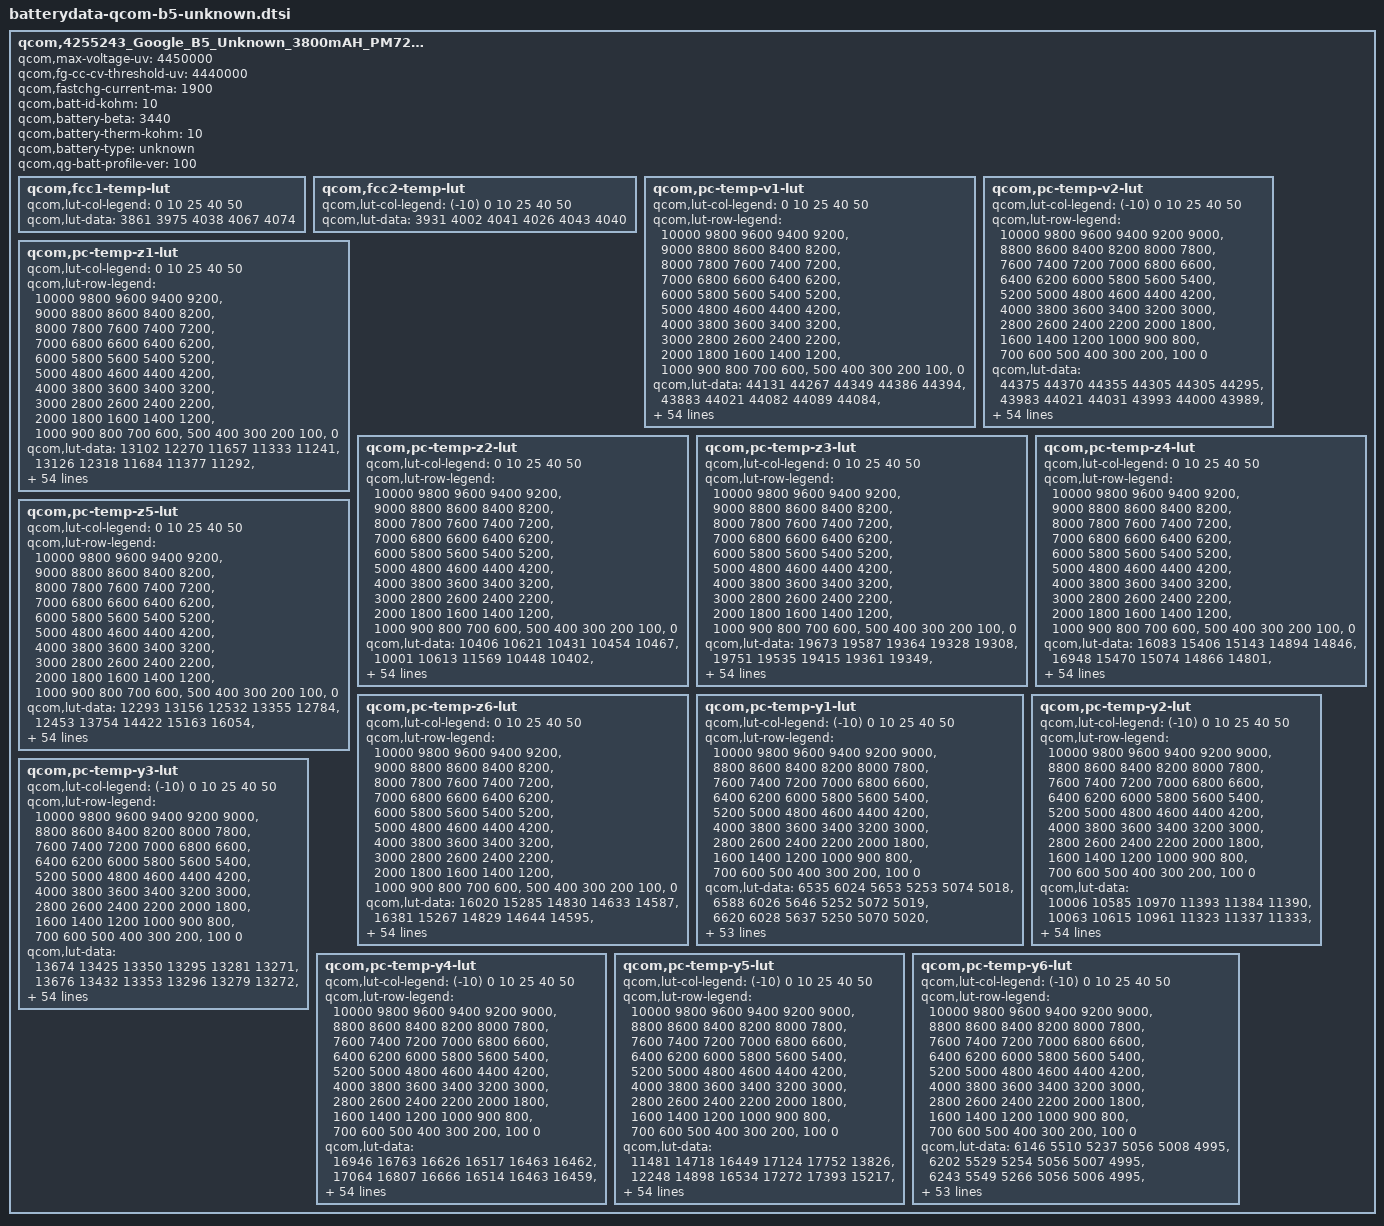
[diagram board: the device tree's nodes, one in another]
// SPDX-License-Identifier: GPL-2.0
qcom,4255243_Google_B5_Unknown_3800mAH_PM7250 {
	/* 4255243_Google_B5_ATL_3800mAH_PM7250_Nov13th2019 */
	qcom,max-voltage-uv = <4450000>;
	qcom,fg-cc-cv-threshold-uv = <4440000>;
	qcom,fastchg-current-ma = <1900>;
	qcom,batt-id-kohm = <10>;
	qcom,battery-beta = <3440>;
	qcom,battery-therm-kohm = <10>;
	qcom,battery-type = "unknown";
	qcom,qg-batt-profile-ver = <100>;

	qcom,fcc1-temp-lut {
		qcom,lut-col-legend = <0 10 25 40 50>;
		qcom,lut-data = <3861 3975 4038 4067 4074>;
	};

	qcom,fcc2-temp-lut {
		qcom,lut-col-legend = <(-10) 0 10 25 40 50>;
		qcom,lut-data = <3931 4002 4041 4026 4043 4040>;
	};

	qcom,pc-temp-v1-lut {
		qcom,lut-col-legend = <0 10 25 40 50>;
		qcom,lut-row-legend = <10000 9800 9600 9400 9200>,
			<9000 8800 8600 8400 8200>,
			<8000 7800 7600 7400 7200>,
			<7000 6800 6600 6400 6200>,
			<6000 5800 5600 5400 5200>,
			<5000 4800 4600 4400 4200>,
			<4000 3800 3600 3400 3200>,
			<3000 2800 2600 2400 2200>,
			<2000 1800 1600 1400 1200>,
			<1000 900 800 700 600>,
			<500 400 300 200 100>,
			<0>;
		qcom,lut-data = <44131 44267 44349 44386 44394>,
			<43883 44021 44082 44089 44084>,
			<43643 43780 43850 43846 43840>,
			<43408 43553 43614 43625 43620>,
			<43167 43319 43382 43402 43400>,
			<42924 43078 43150 43173 43172>,
			<42681 42829 42908 42936 42939>,
			<42437 42581 42660 42689 42699>,
			<42195 42334 42413 42441 42456>,
			<41958 42090 42167 42195 42212>,
			<41727 41850 41925 41952 41967>,
			<41500 41614 41684 41712 41728>,
			<41277 41385 41448 41476 41492>,
			<41062 41164 41220 41246 41261>,
			<40856 40949 41000 41022 41036>,
			<40658 40738 40788 40806 40818>,
			<40457 40533 40582 40597 40609>,
			<40251 40342 40384 40396 40408>,
			<40062 40163 40199 40207 40218>,
			<39903 39991 40021 40027 40036>,
			<39758 39831 39854 39853 39860>,
			<39609 39667 39698 39692 39695>,
			<39459 39469 39507 39513 39517>,
			<39308 39237 39206 39266 39281>,
			<39155 39024 38937 39013 39037>,
			<39000 38822 38814 38859 38874>,
			<38838 38664 38729 38749 38753>,
			<38664 38578 38641 38643 38642>,
			<38536 38516 38553 38540 38537>,
			<38453 38454 38469 38444 38440>,
			<38392 38395 38388 38357 38350>,
			<38344 38339 38314 38279 38268>,
			<38307 38286 38252 38211 38194>,
			<38274 38237 38198 38151 38128>,
			<38245 38197 38150 38095 38065>,
			<38216 38163 38108 38043 38008>,
			<38188 38126 38066 37991 37948>,
			<38161 38091 38026 37939 37879>,
			<38121 38045 37979 37880 37803>,
			<38051 37967 37902 37801 37717>,
			<37958 37856 37789 37696 37619>,
			<37843 37734 37667 37579 37507>,
			<37700 37592 37531 37445 37372>,
			<37537 37425 37372 37289 37217>,
			<37372 37262 37205 37126 37058>,
			<37234 37150 37096 37030 36966>,
			<37196 37119 37068 37006 36945>,
			<37164 37095 37047 36990 36929>,
			<37130 37072 37031 36975 36913>,
			<37099 37042 37000 36939 36871>,
			<37051 36886 36841 36743 36656>,
			<36824 36479 36437 36315 36216>,
			<36347 35891 35865 35738 35639>,
			<35676 35069 35086 34950 34853>,
			<34551 33643 33887 33727 33627>,
			<30000 30000 30000 30000 30000>;
	};

	qcom,pc-temp-v2-lut {
		qcom,lut-col-legend = <(-10) 0 10 25 40 50>;
		qcom,lut-row-legend = <10000 9800 9600 9400 9200 9000>,
			<8800 8600 8400 8200 8000 7800>,
			<7600 7400 7200 7000 6800 6600>,
			<6400 6200 6000 5800 5600 5400>,
			<5200 5000 4800 4600 4400 4200>,
			<4000 3800 3600 3400 3200 3000>,
			<2800 2600 2400 2200 2000 1800>,
			<1600 1400 1200 1000 900 800>,
			<700 600 500 400 300 200>,
			<100 0>;
		qcom,lut-data = <44375 44370 44355 44305 44305 44295>,
			<43983 44021 44031 43993 44000 43989>,
			<43642 43713 43739 43710 43722 43711>,
			<43362 43452 43486 43460 43474 43463>,
			<43130 43231 43265 43239 43252 43241>,
			<42895 43002 43035 43009 43023 43012>,
			<42640 42760 42790 42767 42782 42773>,
			<42388 42514 42543 42522 42538 42531>,
			<42164 42263 42295 42277 42294 42288>,
			<41955 42011 42047 42031 42048 42044>,
			<41706 41772 41803 41791 41809 41804>,
			<41375 41545 41563 41553 41572 41567>,
			<41100 41322 41328 41320 41340 41335>,
			<40972 41101 41097 41091 41112 41107>,
			<40873 40887 40875 40870 40890 40886>,
			<40647 40692 40668 40657 40675 40673>,
			<40166 40507 40469 40452 40467 40468>,
			<39772 40281 40274 40256 40269 40270>,
			<39574 39989 40083 40068 40080 40080>,
			<39410 39708 39872 39882 39897 39897>,
			<39217 39476 39614 39700 39729 39731>,
			<39009 39265 39357 39509 39549 39556>,
			<38812 39067 39142 39276 39311 39323>,
			<38614 38882 38949 39017 39048 39061>,
			<38448 38714 38780 38825 38859 38870>,
			<38340 38560 38632 38683 38717 38726>,
			<38257 38416 38498 38561 38594 38600>,
			<38187 38265 38378 38448 38482 38488>,
			<38127 38126 38268 38347 38382 38387>,
			<38071 38042 38165 38253 38289 38294>,
			<38018 37988 38070 38166 38203 38208>,
			<37966 37941 37985 38088 38126 38130>,
			<37910 37896 37906 38015 38056 38059>,
			<37851 37853 37845 37948 37989 37989>,
			<37791 37807 37806 37886 37925 37923>,
			<37731 37760 37772 37826 37858 37852>,
			<37667 37708 37733 37761 37771 37752>,
			<37597 37651 37692 37693 37668 37627>,
			<37521 37586 37640 37619 37569 37516>,
			<37439 37508 37571 37538 37474 37420>,
			<37351 37419 37483 37456 37391 37336>,
			<37261 37315 37366 37370 37306 37252>,
			<37171 37198 37215 37240 37176 37119>,
			<37089 37064 37051 37107 37046 36986>,
			<37004 36900 36869 36932 36888 36836>,
			<36918 36780 36778 36884 36854 36804>,
			<36871 36741 36746 36866 36846 36793>,
			<36830 36706 36714 36851 36831 36779>,
			<36785 36671 36674 36829 36806 36754>,
			<36743 36630 36608 36779 36745 36689>,
			<36690 36566 36422 36592 36486 36398>,
			<36600 36357 35971 36155 35987 35905>,
			<36417 35780 35321 35549 35334 35249>,
			<36071 34845 34346 34712 34414 34338>,
			<35286 33494 32805 33453 32968 32877>,
			<34418 31790 27248 29348 28016 28016>;
	};

	qcom,pc-temp-z1-lut {
		qcom,lut-col-legend = <0 10 25 40 50>;
		qcom,lut-row-legend = <10000 9800 9600 9400 9200>,
			<9000 8800 8600 8400 8200>,
			<8000 7800 7600 7400 7200>,
			<7000 6800 6600 6400 6200>,
			<6000 5800 5600 5400 5200>,
			<5000 4800 4600 4400 4200>,
			<4000 3800 3600 3400 3200>,
			<3000 2800 2600 2400 2200>,
			<2000 1800 1600 1400 1200>,
			<1000 900 800 700 600>,
			<500 400 300 200 100>,
			<0>;
		qcom,lut-data = <13102 12270 11657 11333 11241>,
			<13126 12318 11684 11377 11292>,
			<13129 12315 11683 11378 11297>,
			<13133 12278 11671 11371 11293>,
			<13133 12259 11659 11363 11291>,
			<13128 12248 11647 11360 11290>,
			<13119 12240 11637 11358 11288>,
			<13094 12232 11628 11356 11287>,
			<13064 12217 11621 11355 11287>,
			<13034 12198 11615 11353 11286>,
			<12999 12191 11612 11352 11286>,
			<12984 12187 11612 11351 11286>,
			<12979 12187 11612 11351 11286>,
			<12977 12192 11612 11351 11286>,
			<12972 12196 11611 11351 11287>,
			<12960 12191 11611 11351 11288>,
			<12957 12181 11612 11352 11289>,
			<12961 12178 11613 11354 11290>,
			<12963 12181 11615 11356 11292>,
			<12965 12184 11618 11358 11294>,
			<12967 12192 11621 11360 11296>,
			<12975 12203 11626 11361 11297>,
			<12998 12206 11630 11363 11298>,
			<13011 12207 11633 11365 11300>,
			<13007 12209 11637 11368 11302>,
			<13000 12212 11641 11371 11305>,
			<12999 12216 11646 11375 11309>,
			<13010 12219 11652 11379 11312>,
			<13016 12223 11658 11383 11315>,
			<13016 12230 11664 11388 11318>,
			<13017 12244 11669 11391 11321>,
			<13022 12255 11673 11395 11324>,
			<13030 12262 11678 11398 11326>,
			<13039 12267 11684 11402 11329>,
			<13054 12270 11688 11406 11332>,
			<13072 12271 11694 11409 11334>,
			<13085 12274 11700 11413 11337>,
			<13096 12282 11708 11416 11340>,
			<13103 12294 11717 11420 11344>,
			<13112 12314 11722 11423 11345>,
			<13122 12335 11727 11426 11347>,
			<13129 12336 11732 11430 11348>,
			<13140 12327 11741 11434 11350>,
			<13180 12340 11748 11436 11352>,
			<13201 12363 11753 11438 11353>,
			<13191 12359 11765 11444 11356>,
			<13196 12368 11760 11445 11356>,
			<13189 12358 11763 11445 11356>,
			<13199 12364 11766 11445 11358>,
			<13158 12360 11770 11448 11360>,
			<13195 12384 11780 11453 11363>,
			<13225 12388 11788 11461 11369>,
			<13209 12413 11806 11471 11376>,
			<13290 12448 11825 11484 11388>,
			<13290 12448 11825 11484 11388>,
			<13290 12448 11825 11484 11388>;
	};

	qcom,pc-temp-z2-lut {
		qcom,lut-col-legend = <0 10 25 40 50>;
		qcom,lut-row-legend = <10000 9800 9600 9400 9200>,
			<9000 8800 8600 8400 8200>,
			<8000 7800 7600 7400 7200>,
			<7000 6800 6600 6400 6200>,
			<6000 5800 5600 5400 5200>,
			<5000 4800 4600 4400 4200>,
			<4000 3800 3600 3400 3200>,
			<3000 2800 2600 2400 2200>,
			<2000 1800 1600 1400 1200>,
			<1000 900 800 700 600>,
			<500 400 300 200 100>,
			<0>;
		qcom,lut-data = <10406 10621 10431 10454 10467>,
			<10001 10613 11569 10448 10402>,
			<10032 10256 11084 10547 10437>,
			<10080 10223 10461 10531 10469>,
			<10120 10182 10382 10696 10584>,
			<10160 10148 10343 10889 10514>,
			<10173 10115 10308 10905 10464>,
			<10167 10097 10279 10629 10442>,
			<10159 10093 10284 10438 10418>,
			<10148 10091 10434 10434 10362>,
			<10132 10095 10570 10434 10302>,
			<10115 10113 10609 10512 10303>,
			<10096 10131 10633 10741 10335>,
			<10079 10144 10637 10838 10353>,
			<10063 10156 10629 10825 10360>,
			<10049 10168 10632 10820 10365>,
			<10044 10181 10669 10868 10382>,
			<10040 10212 10701 10918 10405>,
			<10038 10306 10620 10827 10421>,
			<10043 10366 10475 10531 10442>,
			<10052 10335 10454 10441 10465>,
			<10060 10290 10458 10454 10499>,
			<10069 10304 10462 10462 10527>,
			<10080 10342 10470 10446 10537>,
			<10100 10354 10477 10424 10541>,
			<10122 10339 10455 10449 10554>,
			<10136 10321 10411 10538 10598>,
			<10147 10309 10419 10591 10602>,
			<10154 10299 10509 10616 10496>,
			<10160 10299 10554 10627 10401>,
			<10164 10313 10536 10583 10376>,
			<10168 10325 10513 10518 10361>,
			<10171 10331 10500 10503 10364>,
			<10174 10336 10485 10503 10381>,
			<10177 10339 10485 10519 10410>,
			<10180 10342 10506 10604 10473>,
			<10184 10346 10530 10686 10549>,
			<10189 10353 10549 10723 10633>,
			<10196 10362 10571 10752 10710>,
			<10210 10376 10605 10787 10724>,
			<10227 10391 10645 10825 10701>,
			<10240 10392 10653 10832 10691>,
			<10255 10388 10644 10801 10686>,
			<10280 10394 10644 10790 10674>,
			<10438 10446 10659 10794 10653>,
			<10648 10609 10731 10733 10687>,
			<10575 10637 10717 10710 10689>,
			<10487 10682 10685 10701 10673>,
			<10382 10889 10678 10692 10685>,
			<10361 11053 10690 10760 10784>,
			<10269 10905 10869 10724 10618>,
			<10257 10876 10933 10608 10441>,
			<10148 10743 10925 10515 10370>,
			<9981 10452 10896 10435 10355>,
			<9981 10452 10896 10435 10355>,
			<9981 10452 10896 10435 10355>;
	};

	qcom,pc-temp-z3-lut {
		qcom,lut-col-legend = <0 10 25 40 50>;
		qcom,lut-row-legend = <10000 9800 9600 9400 9200>,
			<9000 8800 8600 8400 8200>,
			<8000 7800 7600 7400 7200>,
			<7000 6800 6600 6400 6200>,
			<6000 5800 5600 5400 5200>,
			<5000 4800 4600 4400 4200>,
			<4000 3800 3600 3400 3200>,
			<3000 2800 2600 2400 2200>,
			<2000 1800 1600 1400 1200>,
			<1000 900 800 700 600>,
			<500 400 300 200 100>,
			<0>;
		qcom,lut-data = <19673 19587 19364 19328 19308>,
			<19751 19535 19415 19361 19349>,
			<19846 19637 19437 19379 19355>,
			<19895 19678 19518 19389 19362>,
			<19885 19689 19522 19437 19396>,
			<19844 19691 19523 19447 19399>,
			<19809 19690 19521 19448 19399>,
			<19779 19689 19517 19435 19392>,
			<19761 19682 19513 19420 19382>,
			<19760 19667 19510 19409 19377>,
			<19760 19653 19506 19399 19372>,
			<19763 19637 19501 19399 19367>,
			<19776 19623 19495 19406 19362>,
			<19790 19608 19485 19405 19358>,
			<19800 19596 19471 19396 19355>,
			<19811 19592 19463 19389 19351>,
			<19812 19589 19459 19387 19346>,
			<19800 19588 19456 19384 19341>,
			<19788 19585 19445 19376 19338>,
			<19777 19581 19431 19361 19336>,
			<19769 19572 19425 19356 19335>,
			<19767 19561 19422 19355 19336>,
			<19770 19567 19421 19354 19337>,
			<19772 19591 19437 19353 19332>,
			<19775 19600 19451 19352 19324>,
			<19777 19598 19440 19349 19326>,
			<19782 19593 19417 19342 19337>,
			<19791 19585 19413 19342 19347>,
			<19796 19573 19419 19372 19359>,
			<19792 19570 19426 19394 19366>,
			<19785 19569 19446 19394 19365>,
			<19779 19569 19464 19392 19361>,
			<19770 19573 19462 19388 19357>,
			<19763 19577 19456 19379 19351>,
			<19758 19576 19450 19372 19346>,
			<19752 19572 19444 19369 19341>,
			<19746 19569 19438 19366 19339>,
			<19738 19566 19434 19364 19340>,
			<19730 19563 19431 19362 19342>,
			<19722 19557 19428 19361 19342>,
			<19713 19549 19426 19361 19342>,
			<19701 19544 19423 19360 19341>,
			<19687 19541 19419 19356 19336>,
			<19669 19534 19414 19356 19336>,
			<19606 19513 19406 19357 19339>,
			<19524 19466 19387 19341 19331>,
			<19425 19450 19385 19339 19323>,
			<19327 19430 19383 19337 19322>,
			<19316 19361 19375 19332 19320>,
			<19312 19329 19371 19327 19313>,
			<19307 19385 19349 19338 19331>,
			<19317 19344 19336 19346 19344>,
			<19325 19331 19331 19349 19346>,
			<19357 19344 19324 19351 19334>,
			<19357 19344 19324 19351 19334>,
			<19357 19344 19324 19351 19334>;
	};

	qcom,pc-temp-z4-lut {
		qcom,lut-col-legend = <0 10 25 40 50>;
		qcom,lut-row-legend = <10000 9800 9600 9400 9200>,
			<9000 8800 8600 8400 8200>,
			<8000 7800 7600 7400 7200>,
			<7000 6800 6600 6400 6200>,
			<6000 5800 5600 5400 5200>,
			<5000 4800 4600 4400 4200>,
			<4000 3800 3600 3400 3200>,
			<3000 2800 2600 2400 2200>,
			<2000 1800 1600 1400 1200>,
			<1000 900 800 700 600>,
			<500 400 300 200 100>,
			<0>;
		qcom,lut-data = <16083 15406 15143 14894 14846>,
			<16948 15470 15074 14866 14801>,
			<16671 15464 14929 14807 14759>,
			<16275 15551 15086 14801 14743>,
			<16037 15332 15035 14860 14813>,
			<15851 15179 14943 14797 14781>,
			<15701 15080 14888 14767 14758>,
			<15582 15006 14848 14755 14743>,
			<15478 14952 14812 14747 14733>,
			<15379 14909 14773 14743 14727>,
			<15286 14872 14744 14738 14722>,
			<15204 14838 14729 14725 14716>,
			<15130 14819 14718 14699 14709>,
			<15062 14811 14714 14685 14702>,
			<14992 14805 14712 14681 14694>,
			<14929 14796 14710 14677 14687>,
			<14908 14787 14701 14669 14681>,
			<14902 14776 14693 14660 14676>,
			<14896 14755 14697 14659 14669>,
			<14878 14742 14707 14669 14662>,
			<14851 14740 14710 14674 14659>,
			<14831 14742 14711 14676 14661>,
			<14813 14756 14717 14680 14663>,
			<14805 14788 14805 14745 14721>,
			<14809 14825 14887 14833 14808>,
			<14820 14877 14888 14841 14813>,
			<14842 14911 14883 14835 14791>,
			<14889 14904 14874 14823 14766>,
			<14911 14885 14849 14775 14736>,
			<14910 14867 14820 14731 14710>,
			<14908 14849 14784 14713 14696>,
			<14903 14832 14754 14701 14686>,
			<14889 14817 14746 14696 14679>,
			<14874 14803 14742 14692 14674>,
			<14861 14794 14741 14691 14672>,
			<14848 14786 14740 14693 14675>,
			<14834 14780 14740 14696 14679>,
			<14820 14773 14741 14702 14688>,
			<14806 14770 14742 14709 14698>,
			<14794 14769 14746 14716 14701>,
			<14782 14769 14753 14722 14702>,
			<14774 14764 14753 14722 14701>,
			<14766 14747 14739 14714 14698>,
			<14750 14734 14730 14710 14697>,
			<14738 14718 14721 14709 14697>,
			<14738 14688 14687 14685 14675>,
			<14848 14696 14676 14676 14672>,
			<14949 14705 14664 14659 14654>,
			<14956 14773 14655 14643 14636>,
			<14957 14803 14653 14643 14637>,
			<14953 14745 14692 14656 14641>,
			<14947 14803 14717 14657 14638>,
			<14964 14830 14723 14654 14637>,
			<14961 14834 14733 14653 14647>,
			<14961 14834 14733 14653 14647>,
			<14961 14834 14733 14653 14647>;
	};

	qcom,pc-temp-z5-lut {
		qcom,lut-col-legend = <0 10 25 40 50>;
		qcom,lut-row-legend = <10000 9800 9600 9400 9200>,
			<9000 8800 8600 8400 8200>,
			<8000 7800 7600 7400 7200>,
			<7000 6800 6600 6400 6200>,
			<6000 5800 5600 5400 5200>,
			<5000 4800 4600 4400 4200>,
			<4000 3800 3600 3400 3200>,
			<3000 2800 2600 2400 2200>,
			<2000 1800 1600 1400 1200>,
			<1000 900 800 700 600>,
			<500 400 300 200 100>,
			<0>;
		qcom,lut-data = <12293 13156 12532 13355 12784>,
			<12453 13754 14422 15163 16054>,
			<12957 15106 16018 17844 18301>,
			<13338 14528 16301 18627 19942>,
			<13419 15048 16520 18153 18775>,
			<13450 15583 16935 19704 19527>,
			<13489 16172 17347 20324 19800>,
			<13543 16711 17849 20235 19591>,
			<13623 17083 18472 19921 19374>,
			<13776 17433 20289 19310 19290>,
			<14050 18043 22195 18744 19223>,
			<14403 18972 23696 19476 19130>,
			<14947 19389 24901 22073 19020>,
			<15649 19407 24723 23917 19009>,
			<16772 19429 23593 24484 19328>,
			<18150 20112 23210 25234 19581>,
			<18754 21600 24318 27271 19534>,
			<18981 22288 25461 29264 19455>,
			<19203 22460 24598 27985 19688>,
			<19559 22841 22772 22979 20755>,
			<20120 23891 22728 21645 22004>,
			<21309 25775 23078 22313 23760>,
			<24451 31115 23929 22704 24817>,
			<28024 42137 29597 21995 22069>,
			<31436 45946 34682 20539 17581>,
			<34969 41961 30489 18616 16262>,
			<38584 36627 21789 15878 15607>,
			<42636 31886 19364 15234 15529>,
			<44278 27483 18860 17213 16829>,
			<42459 26419 18904 19659 18539>,
			<39543 26203 22395 21826 19960>,
			<37381 26160 27000 23918 21385>,
			<35429 28001 29443 25287 22758>,
			<34140 30691 31248 26290 24095>,
			<33403 32017 32297 27538 25237>,
			<32829 32926 33057 29459 26298>,
			<32177 33643 33338 30530 26983>,
			<31538 34328 32888 29718 27123>,
			<31436 34681 32003 28065 26935>,
			<32569 33964 30626 26338 26056>,
			<33604 32664 28655 24322 23847>,
			<32894 32222 27653 23135 22200>,
			<31493 32071 27269 22530 21029>,
			<31136 31706 26227 22021 20371>,
			<28593 30408 25013 21535 20103>,
			<22210 27405 26445 21039 20567>,
			<15973 23201 25897 21501 18989>,
			<12140 18853 26173 22734 20922>,
			<11837 14214 24737 25103 24909>,
			<11756 12676 23814 24037 23376>,
			<11724 15263 17524 20441 22764>,
			<11899 13138 14566 19640 24866>,
			<11819 12455 13907 19931 24559>,
			<12099 12583 13302 19594 18586>,
			<12099 12583 13302 19594 18586>,
			<12099 12583 13302 19594 18586>;
	};

	qcom,pc-temp-z6-lut {
		qcom,lut-col-legend = <0 10 25 40 50>;
		qcom,lut-row-legend = <10000 9800 9600 9400 9200>,
			<9000 8800 8600 8400 8200>,
			<8000 7800 7600 7400 7200>,
			<7000 6800 6600 6400 6200>,
			<6000 5800 5600 5400 5200>,
			<5000 4800 4600 4400 4200>,
			<4000 3800 3600 3400 3200>,
			<3000 2800 2600 2400 2200>,
			<2000 1800 1600 1400 1200>,
			<1000 900 800 700 600>,
			<500 400 300 200 100>,
			<0>;
		qcom,lut-data = <16020 15285 14830 14633 14587>,
			<16381 15267 14829 14644 14595>,
			<16273 15301 14774 14627 14580>,
			<16105 15342 14878 14629 14576>,
			<15974 15240 14856 14677 14625>,
			<15851 15165 14814 14660 14615>,
			<15749 15114 14787 14645 14604>,
			<15667 15071 14765 14632 14594>,
			<15597 15035 14746 14621 14585>,
			<15537 15004 14727 14613 14579>,
			<15485 14977 14712 14606 14574>,
			<15444 14951 14702 14599 14568>,
			<15411 14934 14694 14592 14563>,
			<15382 14923 14686 14585 14557>,
			<15353 14914 14678 14579 14552>,
			<15326 14907 14671 14573 14547>,
			<15311 14900 14666 14568 14541>,
			<15303 14893 14661 14563 14536>,
			<15295 14883 14657 14558 14532>,
			<15282 14875 14653 14554 14527>,
			<15269 14872 14653 14553 14526>,
			<15265 14870 14652 14554 14527>,
			<15264 14877 14655 14555 14528>,
			<15263 14906 14701 14583 14552>,
			<15268 14931 14745 14621 14586>,
			<15278 14953 14741 14623 14589>,
			<15293 14966 14730 14619 14586>,
			<15321 14961 14722 14614 14582>,
			<15334 14948 14716 14609 14576>,
			<15334 14940 14711 14604 14570>,
			<15333 14934 14707 14598 14564>,
			<15330 14929 14704 14592 14558>,
			<15321 14926 14700 14586 14552>,
			<15314 14923 14696 14580 14546>,
			<15309 14920 14693 14577 14543>,
			<15305 14917 14690 14576 14542>,
			<15301 14916 14688 14576 14542>,
			<15296 14916 14688 14577 14546>,
			<15295 14916 14688 14580 14552>,
			<15294 14916 14690 14582 14553>,
			<15294 14916 14693 14585 14553>,
			<15293 14915 14693 14586 14553>,
			<15292 14912 14687 14581 14549>,
			<15287 14907 14682 14580 14549>,
			<15264 14897 14677 14580 14551>,
			<15236 14868 14655 14562 14538>,
			<15232 14863 14651 14557 14532>,
			<15227 14858 14644 14549 14524>,
			<15225 14853 14637 14539 14514>,
			<15227 14853 14636 14538 14512>,
			<15232 14860 14644 14549 14524>,
			<15245 14872 14652 14556 14532>,
			<15269 14886 14657 14559 14535>,
			<15304 14911 14663 14562 14536>,
			<15304 14911 14663 14562 14536>,
			<15304 14911 14663 14562 14536>;
	};

	qcom,pc-temp-y1-lut {
		qcom,lut-col-legend = <(-10) 0 10 25 40 50>;
		qcom,lut-row-legend = <10000 9800 9600 9400 9200 9000>,
			<8800 8600 8400 8200 8000 7800>,
			<7600 7400 7200 7000 6800 6600>,
			<6400 6200 6000 5800 5600 5400>,
			<5200 5000 4800 4600 4400 4200>,
			<4000 3800 3600 3400 3200 3000>,
			<2800 2600 2400 2200 2000 1800>,
			<1600 1400 1200 1000 900 800>,
			<700 600 500 400 300 200>,
			<100 0>;
		qcom,lut-data = <6535 6024 5653 5253 5074 5018>,
			<6588 6026 5646 5252 5072 5019>,
			<6620 6028 5637 5250 5070 5020>,
			<6638 6030 5629 5247 5068 5020>,
			<6645 6032 5623 5245 5066 5019>,
			<6646 6034 5623 5241 5064 5019>,
			<6628 6036 5626 5237 5062 5018>,
			<6609 6037 5628 5234 5060 5017>,
			<6617 6034 5620 5230 5059 5016>,
			<6635 6026 5607 5228 5058 5015>,
			<6640 6025 5606 5225 5057 5015>,
			<6632 6026 5610 5223 5056 5015>,
			<6626 6027 5612 5221 5056 5016>,
			<6638 6035 5609 5220 5056 5016>,
			<6662 6043 5605 5220 5056 5016>,
			<6670 6046 5603 5220 5056 5016>,
			<6664 6047 5602 5219 5056 5015>,
			<6660 6045 5604 5220 5056 5015>,
			<6660 6036 5608 5223 5057 5017>,
			<6659 6030 5611 5225 5059 5018>,
			<6659 6036 5612 5227 5059 5019>,
			<6658 6046 5613 5230 5060 5019>,
			<6657 6045 5613 5233 5061 5019>,
			<6644 6038 5616 5236 5062 5020>,
			<6632 6038 5620 5238 5063 5021>,
			<6635 6050 5625 5241 5065 5023>,
			<6642 6061 5630 5243 5067 5025>,
			<6647 6066 5634 5246 5068 5026>,
			<6661 6070 5637 5250 5070 5027>,
			<6670 6070 5637 5255 5072 5028>,
			<6675 6068 5637 5260 5075 5030>,
			<6683 6066 5637 5266 5078 5031>,
			<6681 6061 5640 5271 5080 5033>,
			<6668 6057 5642 5277 5083 5035>,
			<6661 6063 5646 5281 5086 5037>,
			<6667 6076 5650 5285 5089 5039>,
			<6673 6081 5649 5286 5091 5040>,
			<6666 6079 5646 5287 5093 5042>,
			<6647 6074 5647 5289 5094 5043>,
			<6645 6064 5659 5294 5096 5045>,
			<6672 6058 5664 5298 5097 5046>,
			<6681 6074 5666 5300 5098 5046>,
			<6670 6082 5676 5308 5098 5047>,
			<6645 6094 5682 5307 5102 5050>,
			<6679 6097 5689 5315 5105 5050>,
			<6685 6110 5696 5319 5107 5053>,
			<6666 6117 5688 5323 5108 5053>,
			<6723 6124 5697 5326 5109 5054>,
			<6711 6128 5692 5334 5109 5053>,
			<6765 6121 5701 5335 5109 5055>,
			<6793 6154 5702 5338 5110 5055>,
			<6852 6252 5737 5349 5115 5060>,
			<6985 6354 5789 5370 5121 5063>,
			<7138 6512 5922 5390 5129 5072>,
			<7138 6512 5922 5390 5129 5072>,
			<7138 6512 5922 5390 5129 5072>;
	};

	qcom,pc-temp-y2-lut {
		qcom,lut-col-legend = <(-10) 0 10 25 40 50>;
		qcom,lut-row-legend = <10000 9800 9600 9400 9200 9000>,
			<8800 8600 8400 8200 8000 7800>,
			<7600 7400 7200 7000 6800 6600>,
			<6400 6200 6000 5800 5600 5400>,
			<5200 5000 4800 4600 4400 4200>,
			<4000 3800 3600 3400 3200 3000>,
			<2800 2600 2400 2200 2000 1800>,
			<1600 1400 1200 1000 900 800>,
			<700 600 500 400 300 200>,
			<100 0>;
		qcom,lut-data = <10006 10585 10970 11393 11384 11390>,
			<10063 10615 10961 11323 11337 11333>,
			<10133 10641 10948 11251 11270 11258>,
			<10202 10663 10930 11185 11201 11179>,
			<10258 10676 10909 11129 11148 11109>,
			<10289 10679 10885 11090 11124 11061>,
			<10301 10671 10855 11062 11092 11012>,
			<10312 10662 10827 11039 11060 10984>,
			<10338 10659 10807 11017 11040 10989>,
			<10384 10657 10792 10999 11028 10996>,
			<10423 10649 10788 10997 11027 10988>,
			<10476 10628 10786 11000 11029 10974>,
			<10510 10620 10787 11004 11035 10967>,
			<10503 10740 10802 11013 11049 10965>,
			<10482 10872 10830 11026 11060 10965>,
			<10370 10846 10879 11043 11061 10979>,
			<9943 10762 10950 11068 11059 11005>,
			<9699 10750 11009 11106 11072 11015>,
			<9692 10840 11064 11171 11123 11011>,
			<9687 10907 11082 11235 11197 11029>,
			<9682 10919 11058 11299 11354 11176>,
			<9676 10925 11035 11343 11475 11311>,
			<9672 10923 11043 11316 11390 11298>,
			<9669 10914 11063 11247 11222 11263>,
			<9667 10903 11079 11232 11201 11257>,
			<9665 10882 11094 11258 11259 11269>,
			<9664 10868 11102 11283 11310 11289>,
			<9663 10878 11106 11302 11336 11347>,
			<9662 10897 11108 11325 11364 11413>,
			<9661 10893 11097 11353 11425 11468>,
			<9661 10842 11073 11393 11510 11542>,
			<9660 10749 11068 11414 11554 11558>,
			<9659 10364 11072 11431 11585 11554>,
			<9659 9945 11074 11437 11597 11552>,
			<9658 9811 11047 11414 11606 11557>,
			<9658 9728 10999 11379 11615 11558>,
			<9658 9694 10952 11358 11578 11538>,
			<9657 9678 10897 11342 11487 11498>,
			<9657 9670 10830 11329 11440 11473>,
			<9657 9666 10741 11312 11419 11467>,
			<9657 9664 10644 11297 11416 11438>,
			<9657 9661 10537 11287 11424 11394>,
			<9656 9660 10451 11266 11450 11449>,
			<9656 9659 10151 11280 11455 11410>,
			<9656 9658 9839 11195 11420 11477>,
			<9655 9656 9728 11098 11362 11270>,
			<9655 9655 9691 11102 11311 11217>,
			<9654 9655 9676 11107 11275 11130>,
			<9654 9654 9667 11096 11272 11083>,
			<9652 9653 9661 11043 11251 11101>,
			<9650 9652 9657 10982 11208 11113>,
			<9648 9649 9653 10914 11130 11020>,
			<9647 9647 9651 10830 11045 10909>,
			<9647 9647 9648 10714 10964 10822>,
			<9647 9647 9648 10714 10964 10822>,
			<9647 9647 9648 10714 10964 10822>;
	};

	qcom,pc-temp-y3-lut {
		qcom,lut-col-legend = <(-10) 0 10 25 40 50>;
		qcom,lut-row-legend = <10000 9800 9600 9400 9200 9000>,
			<8800 8600 8400 8200 8000 7800>,
			<7600 7400 7200 7000 6800 6600>,
			<6400 6200 6000 5800 5600 5400>,
			<5200 5000 4800 4600 4400 4200>,
			<4000 3800 3600 3400 3200 3000>,
			<2800 2600 2400 2200 2000 1800>,
			<1600 1400 1200 1000 900 800>,
			<700 600 500 400 300 200>,
			<100 0>;
		qcom,lut-data = <13674 13425 13350 13295 13281 13271>,
			<13676 13432 13353 13296 13279 13272>,
			<13677 13438 13357 13298 13279 13274>,
			<13677 13444 13361 13300 13279 13275>,
			<13676 13449 13364 13301 13279 13277>,
			<13675 13452 13366 13302 13279 13277>,
			<13671 13454 13368 13302 13281 13278>,
			<13668 13456 13369 13302 13282 13278>,
			<13670 13456 13371 13303 13283 13279>,
			<13673 13455 13372 13304 13283 13280>,
			<13665 13455 13373 13304 13285 13281>,
			<13578 13454 13374 13305 13289 13282>,
			<13509 13453 13374 13305 13292 13282>,
			<13518 13442 13373 13305 13292 13282>,
			<13535 13430 13372 13306 13292 13282>,
			<13535 13426 13366 13307 13291 13283>,
			<13523 13423 13357 13310 13290 13287>,
			<13516 13419 13357 13310 13290 13287>,
			<13524 13414 13361 13309 13291 13286>,
			<13535 13408 13363 13308 13292 13285>,
			<13537 13401 13355 13310 13294 13288>,
			<13537 13393 13346 13312 13295 13291>,
			<13535 13386 13341 13308 13291 13288>,
			<13523 13380 13338 13300 13282 13281>,
			<13512 13375 13335 13296 13280 13277>,
			<13520 13371 13332 13296 13281 13275>,
			<13544 13365 13330 13295 13281 13274>,
			<13573 13351 13329 13295 13280 13274>,
			<13611 13333 13327 13294 13279 13274>,
			<13657 13331 13326 13294 13278 13274>,
			<13709 13335 13325 13294 13278 13275>,
			<13769 13340 13323 13294 13278 13276>,
			<13832 13346 13322 13294 13278 13275>,
			<13899 13355 13321 13295 13279 13275>,
			<13968 13369 13323 13295 13280 13276>,
			<14040 13395 13328 13294 13281 13276>,
			<14112 13424 13332 13294 13280 13276>,
			<14179 13456 13337 13293 13278 13275>,
			<14244 13496 13342 13293 13277 13274>,
			<14297 13553 13347 13292 13277 13273>,
			<14339 13620 13352 13292 13277 13273>,
			<14380 13696 13356 13293 13278 13275>,
			<14422 13771 13356 13294 13276 13273>,
			<14460 13749 13348 13293 13277 13273>,
			<14446 13899 13363 13292 13275 13272>,
			<14609 14117 13407 13297 13277 13276>,
			<14693 14248 13447 13298 13282 13277>,
			<14816 14398 13497 13303 13284 13281>,
			<15004 14563 13583 13307 13287 13282>,
			<15359 14801 13730 13311 13290 13285>,
			<16426 15347 14004 13313 13286 13280>,
			<20428 18387 14613 13314 13282 13282>,
			<31642 32381 16134 13326 13290 13283>,
			<65535 65535 27916 13336 13291 13287>,
			<65535 65535 27916 13336 13291 13287>,
			<65535 65535 27916 13336 13291 13287>;
	};

	qcom,pc-temp-y4-lut {
		qcom,lut-col-legend = <(-10) 0 10 25 40 50>;
		qcom,lut-row-legend = <10000 9800 9600 9400 9200 9000>,
			<8800 8600 8400 8200 8000 7800>,
			<7600 7400 7200 7000 6800 6600>,
			<6400 6200 6000 5800 5600 5400>,
			<5200 5000 4800 4600 4400 4200>,
			<4000 3800 3600 3400 3200 3000>,
			<2800 2600 2400 2200 2000 1800>,
			<1600 1400 1200 1000 900 800>,
			<700 600 500 400 300 200>,
			<100 0>;
		qcom,lut-data = <16946 16763 16626 16517 16463 16462>,
			<17064 16807 16666 16514 16463 16459>,
			<17225 16890 16710 16511 16463 16454>,
			<17388 16980 16748 16509 16462 16450>,
			<17509 17048 16774 16507 16462 16447>,
			<17547 17067 16779 16507 16461 16446>,
			<17526 17063 16770 16508 16461 16446>,
			<17501 17058 16759 16509 16461 16446>,
			<17493 17049 16749 16511 16463 16447>,
			<17489 17039 16740 16515 16467 16449>,
			<17493 17039 16740 16520 16467 16451>,
			<17546 17053 16744 16527 16467 16455>,
			<17614 17075 16750 16535 16467 16459>,
			<17683 17126 16760 16546 16473 16466>,
			<17749 17180 16777 16558 16482 16472>,
			<17704 17206 16831 16571 16493 16475>,
			<17412 17225 16903 16587 16506 16478>,
			<17211 17212 16914 16611 16519 16485>,
			<17173 17071 16905 16649 16532 16498>,
			<17145 16942 16888 16675 16551 16514>,
			<17089 16892 16821 16686 16586 16539>,
			<17009 16856 16739 16692 16612 16557>,
			<16940 16817 16688 16650 16577 16533>,
			<16873 16778 16647 16546 16503 16481>,
			<16833 16742 16623 16509 16476 16463>,
			<16833 16707 16607 16500 16465 16457>,
			<16835 16675 16597 16497 16462 16455>,
			<16836 16642 16590 16500 16466 16457>,
			<16839 16615 16585 16505 16473 16462>,
			<16843 16612 16575 16511 16481 16468>,
			<16846 16618 16562 16519 16491 16475>,
			<16851 16627 16549 16526 16502 16483>,
			<16858 16657 16533 16535 16514 16495>,
			<16869 16696 16526 16541 16523 16505>,
			<16876 16723 16539 16545 16529 16512>,
			<16880 16746 16563 16547 16533 16517>,
			<16882 16770 16589 16543 16523 16507>,
			<16882 16797 16622 16525 16497 16480>,
			<16882 16811 16651 16510 16479 16468>,
			<16881 16808 16679 16496 16467 16463>,
			<16874 16804 16686 16495 16467 16464>,
			<16867 16796 16686 16508 16472 16467>,
			<16861 16779 16646 16500 16463 16457>,
			<16848 16730 16638 16495 16464 16457>,
			<16825 16716 16655 16487 16445 16437>,
			<16820 16719 16677 16499 16456 16446>,
			<16837 16733 16699 16512 16464 16455>,
			<16843 16752 16728 16529 16472 16463>,
			<16864 16780 16767 16551 16485 16485>,
			<16881 16819 16820 16576 16507 16506>,
			<16960 16869 16866 16560 16469 16452>,
			<17507 17170 16874 16558 16463 16448>,
			<19396 20207 17037 16586 16469 16456>,
			<33008 65535 22934 16636 16496 16485>,
			<33008 65535 22934 16636 16496 16485>,
			<33008 65535 22934 16636 16496 16485>;
	};

	qcom,pc-temp-y5-lut {
		qcom,lut-col-legend = <(-10) 0 10 25 40 50>;
		qcom,lut-row-legend = <10000 9800 9600 9400 9200 9000>,
			<8800 8600 8400 8200 8000 7800>,
			<7600 7400 7200 7000 6800 6600>,
			<6400 6200 6000 5800 5600 5400>,
			<5200 5000 4800 4600 4400 4200>,
			<4000 3800 3600 3400 3200 3000>,
			<2800 2600 2400 2200 2000 1800>,
			<1600 1400 1200 1000 900 800>,
			<700 600 500 400 300 200>,
			<100 0>;
		qcom,lut-data = <11481 14718 16449 17124 17752 13826>,
			<12248 14898 16534 17272 17393 15217>,
			<13004 15073 16588 17240 16727 16444>,
			<13715 15240 16617 17068 16002 17403>,
			<14343 15399 16629 16796 15463 17989>,
			<14850 15552 16630 16451 15332 18088>,
			<15231 15730 16614 15933 15371 17689>,
			<15602 15837 16573 15430 15403 17286>,
			<16245 15697 16459 15087 15178 17108>,
			<17096 15432 16254 14793 14824 16895>,
			<17107 15400 15955 14497 15121 16571>,
			<14825 15497 15482 14207 16372 16078>,
			<13010 15535 15058 13908 16840 15540>,
			<14692 14975 14632 13531 16238 14835>,
			<17666 14358 14382 13257 15404 14390>,
			<17674 15271 14383 13220 14598 14757>,
			<14804 17658 14399 13253 13857 15425>,
			<13188 18538 15017 13285 13645 15299>,
			<14099 18691 17655 13346 13563 14242>,
			<15235 18833 19103 13512 13565 13769>,
			<15324 19102 19330 16136 14161 14294>,
			<15216 19397 19506 18973 15083 15191>,
			<14979 19570 19829 19036 16039 16611>,
			<13648 19686 20198 18819 17065 18322>,
			<12320 19842 20322 18771 17815 18468>,
			<11959 20146 20271 18910 18567 17428>,
			<11750 20355 20233 18992 18841 16501>,
			<11695 17996 20265 18806 17965 15864>,
			<11748 13740 20359 18575 16815 15474>,
			<11818 12991 20741 18570 16208 15556>,
			<11962 13183 21380 18637 15770 15797>,
			<12166 13276 21253 18756 15736 15871>,
			<12256 13034 19516 19087 16066 15732>,
			<12302 12764 18300 19544 16561 15724>,
			<12379 12823 18170 20277 17649 16309>,
			<12625 13030 18203 21017 18619 17031>,
			<12873 13179 18141 21062 18554 17318>,
			<12964 13339 17992 20683 18269 17500>,
			<13033 13462 17791 20273 18264 17528>,
			<13028 13622 17466 19218 18675 17243>,
			<12829 13720 17222 18285 18538 17587>,
			<12596 13513 17003 17561 17773 18415>,
			<12327 13396 16610 17835 16683 16582>,
			<12248 13039 14705 17875 16725 16093>,
			<11922 12784 13437 17762 18620 19744>,
			<12130 12713 13336 18949 16560 17585>,
			<11843 12575 13176 17300 17316 16235>,
			<11951 12552 13025 16921 16728 17555>,
			<11862 12483 12972 16201 16886 16776>,
			<12076 12491 12977 15419 17084 16926>,
			<11953 12722 12714 16352 17684 17796>,
			<10651 11417 12658 16994 16967 19911>,
			<9579 9431 12066 18742 21641 20002>,
			<9059 8825 9465 18362 20896 22885>,
			<9059 8825 9465 18362 20896 22885>,
			<9059 8825 9465 18362 20896 22885>;
	};

	qcom,pc-temp-y6-lut {
		qcom,lut-col-legend = <(-10) 0 10 25 40 50>;
		qcom,lut-row-legend = <10000 9800 9600 9400 9200 9000>,
			<8800 8600 8400 8200 8000 7800>,
			<7600 7400 7200 7000 6800 6600>,
			<6400 6200 6000 5800 5600 5400>,
			<5200 5000 4800 4600 4400 4200>,
			<4000 3800 3600 3400 3200 3000>,
			<2800 2600 2400 2200 2000 1800>,
			<1600 1400 1200 1000 900 800>,
			<700 600 500 400 300 200>,
			<100 0>;
		qcom,lut-data = <6146 5510 5237 5056 5008 4995>,
			<6202 5529 5254 5056 5007 4995>,
			<6243 5549 5266 5056 5006 4995>,
			<6271 5566 5274 5056 5006 4995>,
			<6286 5577 5278 5056 5006 4995>,
			<6290 5580 5279 5056 5006 4995>,
			<6273 5576 5274 5056 5006 4996>,
			<6254 5570 5268 5056 5007 4996>,
			<6251 5563 5263 5057 5008 4997>,
			<6252 5556 5258 5058 5010 4998>,
			<6246 5555 5257 5060 5011 5000>,
			<6206 5555 5256 5062 5014 5001>,
			<6175 5555 5255 5064 5016 5003>,
			<6201 5560 5257 5067 5018 5004>,
			<6247 5567 5259 5071 5021 5006>,
			<6233 5572 5269 5075 5023 5009>,
			<6118 5576 5283 5082 5026 5012>,
			<6053 5572 5285 5089 5030 5014>,
			<6057 5533 5285 5099 5034 5017>,
			<6061 5495 5283 5106 5041 5021>,
			<6058 5478 5258 5110 5052 5030>,
			<6045 5465 5228 5113 5060 5037>,
			<6034 5455 5211 5099 5046 5028>,
			<6026 5446 5198 5063 5019 5007>,
			<6022 5440 5192 5051 5010 4999>,
			<6035 5436 5187 5048 5007 4996>,
			<6071 5433 5185 5047 5006 4995>,
			<6107 5427 5186 5048 5007 4996>,
			<6145 5421 5186 5050 5008 4997>,
			<6187 5424 5185 5052 5010 4999>,
			<6235 5447 5184 5055 5013 5002>,
			<6287 5475 5183 5058 5016 5005>,
			<6341 5506 5183 5062 5020 5008>,
			<6399 5543 5183 5065 5024 5011>,
			<6458 5586 5193 5067 5027 5014>,
			<6516 5637 5211 5068 5028 5015>,
			<6573 5694 5231 5067 5025 5012>,
			<6627 5760 5256 5063 5016 5004>,
			<6677 5829 5284 5059 5011 5000>,
			<6720 5899 5315 5056 5007 4998>,
			<6755 5973 5349 5056 5008 4999>,
			<6790 6050 5379 5062 5010 5001>,
			<6824 6121 5385 5062 5006 4997>,
			<6853 6099 5389 5060 5007 4997>,
			<6853 6228 5447 5058 5001 4991>,
			<6984 6412 5548 5069 5006 4996>,
			<7061 6528 5618 5074 5011 5000>,
			<7177 6664 5708 5084 5016 5005>,
			<7344 6814 5832 5095 5022 5013>,
			<7659 7028 6008 5107 5030 5021>,
			<8577 7508 6285 5106 5016 5002>,
			<11820 9974 6810 5111 5013 5002>,
			<20273 20593 8087 5135 5021 5006>,
			<52332 65535 18272 5170 5031 5019>,
			<52332 65535 18272 5170 5031 5019>,
			<52332 65535 18272 5170 5031 5019>;
	};

};
